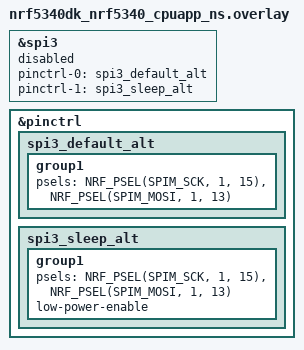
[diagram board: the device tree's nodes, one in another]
/* Copyright (c) 2022 Nordic Semiconductor ASA
 *
 * SPDX-License-Identifier: LicenseRef-Nordic-5-Clause
 */

 &spi3 {
	/* Disabled in non-secure image. */
	status = "disabled";
	pinctrl-0 = <&spi3_default_alt>;
	pinctrl-1 = <&spi3_sleep_alt>;
	pinctrl-names = "default", "sleep";
};

&pinctrl {
	spi3_default_alt: spi3_default_alt {
		group1 {
			psels = <NRF_PSEL(SPIM_SCK, 1, 15)>,
				<NRF_PSEL(SPIM_MOSI, 1, 13)>;
		};
	};

	spi3_sleep_alt: spi3_sleep_alt {
		group1 {
			psels = <NRF_PSEL(SPIM_SCK, 1, 15)>,
				<NRF_PSEL(SPIM_MOSI, 1, 13)>;
			low-power-enable;
		};
	};

};
